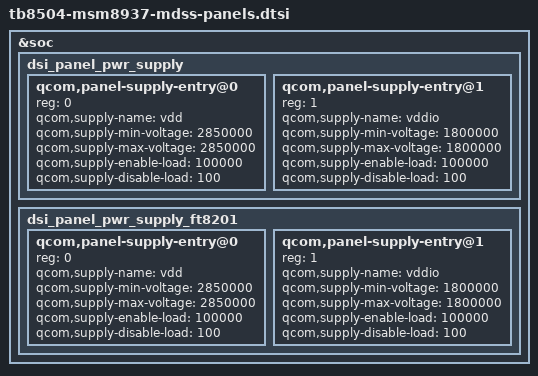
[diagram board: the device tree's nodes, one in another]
#include "dsi-panel-auo-b080eab02_0_rm68200_800p-video.dtsi"
#include "dsi-panel-hx83100a-800p-video.dtsi"
#include "dsi-panel-ft8201-720p-video.dtsi"
&soc {
	dsi_panel_pwr_supply: dsi_panel_pwr_supply {
		#address-cells = <1>;
		#size-cells = <0>;

		qcom,panel-supply-entry@0 {
			reg = <0>;
			qcom,supply-name = "vdd";
			qcom,supply-min-voltage = <2850000>;
			qcom,supply-max-voltage = <2850000>;
			qcom,supply-enable-load = <100000>;
			qcom,supply-disable-load = <100>;
		};

		qcom,panel-supply-entry@1 {
			reg = <1>;
			qcom,supply-name = "vddio";
			qcom,supply-min-voltage = <1800000>;
			qcom,supply-max-voltage = <1800000>;
			qcom,supply-enable-load = <100000>;
			qcom,supply-disable-load = <100>;
		};

	};
	dsi_panel_pwr_supply_ft8201: dsi_panel_pwr_supply_ft8201 {
		#address-cells = <1>;
		#size-cells = <0>;

		qcom,panel-supply-entry@0 {
			reg = <0>;
			qcom,supply-name = "vdd";
			qcom,supply-min-voltage = <2850000>;
			qcom,supply-max-voltage = <2850000>;
			qcom,supply-enable-load = <100000>;
			qcom,supply-disable-load = <100>;
		};

		qcom,panel-supply-entry@1 {
			reg = <1>;
			qcom,supply-name = "vddio";
			qcom,supply-min-voltage = <1800000>;
			qcom,supply-max-voltage = <1800000>;
			qcom,supply-enable-load = <100000>;
			qcom,supply-disable-load = <100>;
		};

	};
};
